# cslr_pimpdma register map
Vendor: Texas Instruments
Peripheral module from a debugger description file (folder tci6486).
Registers are 32-bit, read-write, reset 0x0 unless marked. A register's access mark holds for its fields unless they carry their own. Offsets are as the file gives them; lines under a group give offsets from that group; [hi:lo] are bit positions; {n}, {i} and the like mark numbered series; 'fields as' and 'values as' point back to an identical list; <NAME> marks a mode.

## PIM — Proxy for PDMA Registers
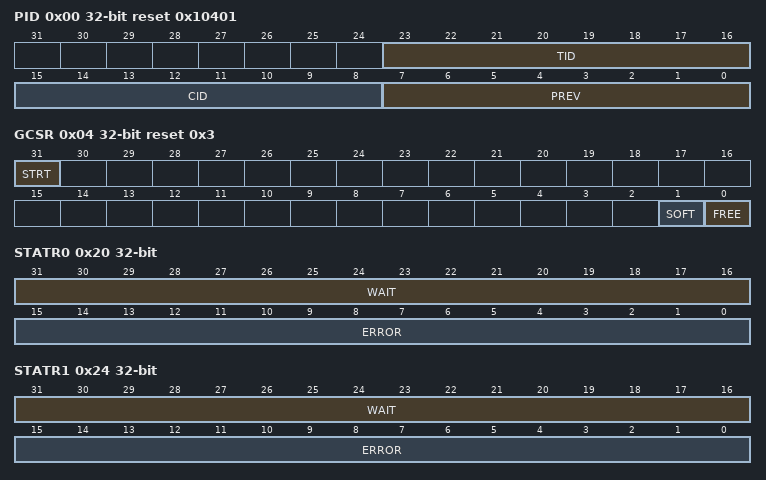
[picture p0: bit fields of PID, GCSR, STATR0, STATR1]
0x00 PID access not given reset 0x10401 — Peripheral Identification
  [23:16] TID ro — Peripheral Type ID
  [15:8] CID ro — Peripheral Class ID
  [7:0] PREV ro — Peripheral Revision Number
0x04 GCSR access not given reset 0x3 — Global Control & Status
  [31] STRT rw — PDMA Start Control
    0=HALTED; 1=ENABLED
  [1] SOFT rw — Soft run selection
    1=HALTED
  [0] FREE rw — Free run selection
    0=HALT; 1=RUN
0x20 STATR0 ro — Statistics Registers
  [31:16] WAIT — Count of PDMA stalls
  [15:0] ERROR — Count for PDMA Errors
0x24 STATR1 ro — Statistics Registers
  fields as STATR0
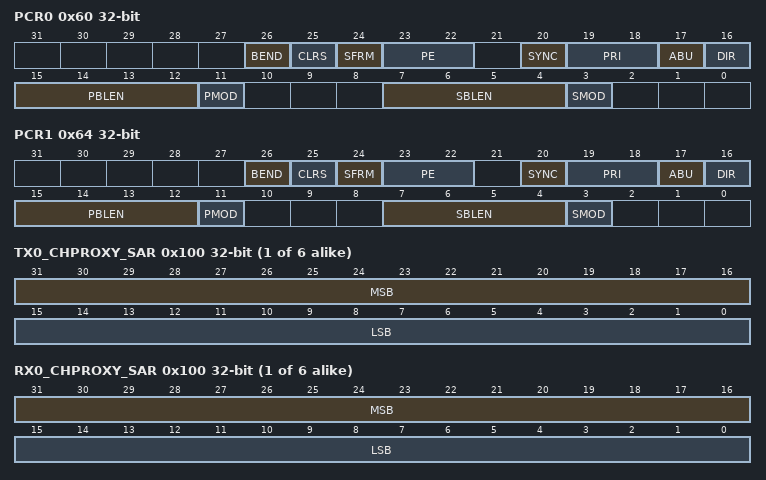
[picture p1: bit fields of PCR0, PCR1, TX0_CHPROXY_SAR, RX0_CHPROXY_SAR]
0x60 PCR0 access not given — Peripheral Control
  [26] BEND rw — Endian Mode Selection
    0=LITTLE_ENDIAN; 1=BIG_ENDIAN
  [25] CLRS rw — Clears Statistics Register
    0=DISABLE; 1=ENABLE
  [24] SFRM rw — Super Frame Sync Select
    0=DISABLE; 1=ENABLE
  [23:22] PE rw — Peripheral Event Control
  [20] SYNC rw — Peripheral Synchronization Start
    0=DISABLE; 1=ENABLE
  [19:18] PRI rw — Priority
    0=LOWEST; 1=LOW; 2=HIGH; 2=HIGHEST
  [17] ABU rw — Enable Control For Auto Buffer
    0=DISABLE; 1=ENABLE
  [16] DIR rw — Direction Of Transfer
    0=SW_TO_PERI; 1=PERI_TO_SW
  [15:12] PBLEN rw — Peripheral Burst Length
  [11] PMOD rw — Peripheral Address Modification
    0=INCR; 1=CONST
  [7:4] SBLEN rw — Switch Burst Length
  [3] SMOD rw — Switch Address Modification
    0=INCR; 1=CONST
0x64 PCR1 access not given — Peripheral Control
  fields as PCR0
{0x100+0x10*i} TX{i}_CHPROXY_SAR (i=0..5) — Switch Address
  [31:16] MSB — Switch Address MSB's
  [15:0] LSB — Switch Address LSB's
    1=CLR
{0x100+0x10*i} RX{i}_CHPROXY_SAR (i=0..5) — Switch Address
  fields as TX0_CHPROXY_SAR
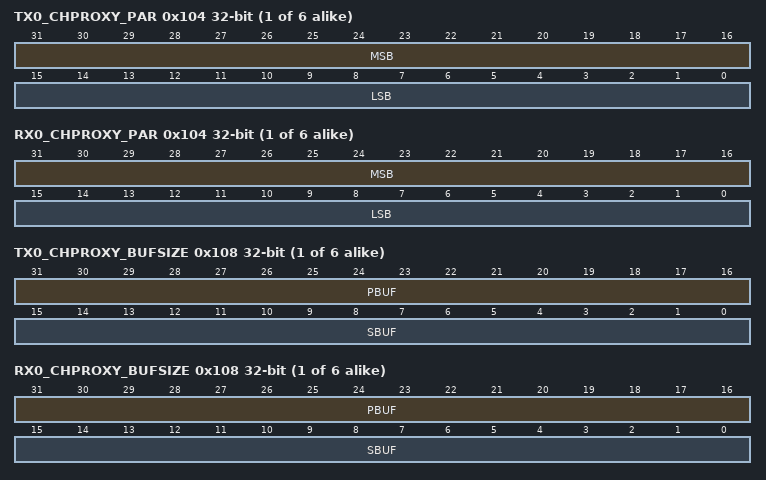
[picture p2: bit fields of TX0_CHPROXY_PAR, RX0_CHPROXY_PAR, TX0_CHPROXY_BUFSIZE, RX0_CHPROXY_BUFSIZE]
{0x104+0x10*i} TX{i}_CHPROXY_PAR (i=0..5) — Switch Address
  [31:16] MSB — Peripheral Address MSB's
  [15:0] LSB — Peripheral Address LSB's
    1=CLR
{0x104+0x10*i} RX{i}_CHPROXY_PAR (i=0..5) — Switch Address
  fields as TX0_CHPROXY_PAR
{0x108+0x10*i} TX{i}_CHPROXY_BUFSIZE (i=0..5) — Transfer Count / Buffer Size
  [31:16] PBUF — ABU Mode - Peripheral Buffer Size / Block Mode - 31to27 reserved & 26-16 Xfer Count
  [15:0] SBUF — ABU Mode - Switch buffer Size / Block Mode - 16to0 Xfer Count
{0x108+0x10*i} RX{i}_CHPROXY_BUFSIZE (i=0..5) — Transfer Count / Buffer Size
  fields as TX0_CHPROXY_BUFSIZE
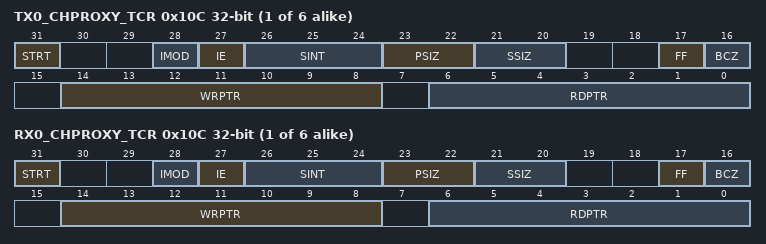
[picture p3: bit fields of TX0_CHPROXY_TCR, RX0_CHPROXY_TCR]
{0x10C+0x10*i} TX{i}_CHPROXY_TCR access not given (i=0..5) — Transfer Control
  [31] STRT rw — Enable / Disable control for Channel
  [28] IMOD rw — Interrupt Mode
  [27] IE rw — Interrupt Enable
  [26:24] SINT rw — Subsystem Interrupt
  [23:22] PSIZ rw — Peripheral Element Size
  [21:20] SSIZ rw — Switch Element Size
  [17] FF rw — FIFO Full Flag - should be initialised to 0
  [16] BCZ rw — Block Count Equal 0 - should be initialised to 0
  [14:8] WRPTR rw — Write Pointer - should be initialised to 0
  [6:0] RDPTR rw — Read Pointer- should be initialised to 0
{0x10C+0x10*i} RX{i}_CHPROXY_TCR access not given (i=0..5) — Transfer Control
  fields as TX0_CHPROXY_TCR
